# CC3200 register map
Vendor: Texas Instruments; Series: SimpleLink; File version: 1.0
Texas Instruments CC3200 SimpleLink Wi-Fi Cortex-M4 device generated from TI CCS target database CC_3200.xml
CPU: CM4 r0p1, little endian, MPU, no FPU, 3 interrupt priority bits
Registers are 32-bit, read-write, reset 0x0 unless marked. A register's access mark holds for its fields unless they carry their own. Offsets are from the block's base; lines under a group give offsets from that group; [hi:lo] are bit positions; {n}, {i} and the like mark numbered series; 'fields as' and 'values as' point back to an identical list; <NAME> marks a mode.

## Memory map
0x40000000 WDT size 0x1000
0x40004000 GPIO size 0x1000 — GPIOA0
0x40005000 GPIO size 0x1000 — GPIOA1
0x40006000 GPIO size 0x1000 — GPIOA2
0x40007000 GPIO size 0x1000 — GPIOA3
0x4000C000 UART size 0x1000 — UARTA0
0x4000D000 UART size 0x1000 — UARTA1
0x40020000 I2C size 0x1000 — I2CA0
0x40024000 GPIO size 0x1000 — GPIOA4
0x40030000 TIMER size 0x1000 — TIMERA0
0x40031000 TIMER size 0x1000 — TIMERA1
0x40032000 TIMER size 0x1000 — TIMERA2
0x40033000 TIMER size 0x1000 — TIMERA3
0x400F5000 STACK_DIE_CTRL size 0x1000
0x400F7000 COMMON_REG size 0x1000
0x400FD000 FLASH_CTRL size 0x1000 — FLASH_CONTROL
0x400FF000 UDMA size 0x1000
0x44010000 MMCHS size 0x1000 — SDHOST
0x44018000 CAMERA size 0x1000
0x4401C000 MCASP size 0x1000 — I2S
0x44020000 MCSPI size 0x1000 — SSPI
0x44021000 MCSPI size 0x1000 — GSPI
0x44022000 MCSPI size 0x1000 — LSPI
0x44025000 APPS_RCM size 0x1000 — ARCM
0x44026000 APPS_CONFIG size 0x1000
0x4402D000 GPRCM size 0x1000
0x4402E000 ADC size 0x1000
0x4402E000 OCP_SHARED size 0x1000
0x4402F000 HIB1P2 size 0x1000
0x4402F000 HIB3P3 size 0x1000
0x44030000 DTHE size 0x1000
0x44035000 SHAMD5 size 0x1000
0x44037000 AES size 0x1000
0x44039000 DES size 0x1000

## ADC
Base 0x4402E000
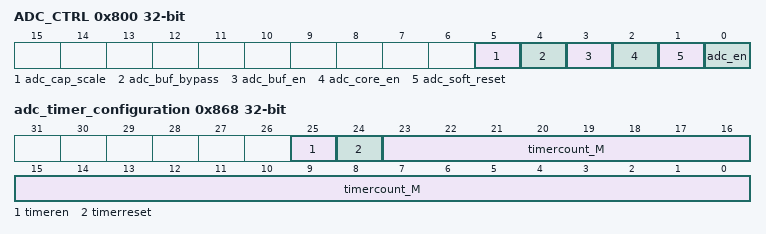
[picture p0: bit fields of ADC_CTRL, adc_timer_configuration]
0x800 ADC_CTRL — ADC_ADC_CTRL
  [5] adc_cap_scale — ADC_ADC_CTRL
  [4] adc_buf_bypass — ADC_ADC_CTRL
  [3] adc_buf_en — ADC_ADC_CTRL
  [2] adc_core_en — ADC_ADC_CTRL
  [1] adc_soft_reset — ADC_ADC_CTRL
  [0] adc_en — ADC_ADC_CTRL
{0x804+4i} adc_ch{i}_gain (i=0..7) — ADC_adc_ch{i}_gain
  [1:0] adc_channel{i}_gain_M
{0x824+4i} adc_ch{i}_irq_en (i=0..7) — ADC_adc_ch{i}_irq_en
  [3:0] adc_channel{i}_irq_en_M
{0x844+4i} adc_ch{i}_irq_status (i=0..7) — ADC_adc_ch{i}_irq_status
  [3:0] adc_channel{i}_irq_status_M
0x864 adc_dma_mode_en — ADC_adc_dma_mode_en
  [7:0] DMA_MODEenable_M
0x868 adc_timer_configuration — ADC_adc_timer_configuration
  [25] timeren — ADC_adc_timer_configuration
  [24] timerreset — ADC_adc_timer_configuration
  [23:0] timercount_M — ADC_adc_timer_configuration
0x870 adc_timer_current_count — ADC_adc_timer_current_count
  [16:0] timercurrentcount_M
{0x874+4i} channel{i}FIFODATA (i=0..7) — ADC_channel{i}FIFODATA
  [31:0] FIFO_RD_DATA_M
{0x894+4i} adc_ch{i}_fifo_lvl (i=0..7) — ADC_adc_ch{i}_fifo_lvl
  [2:0] adc_channel{i}_fifo_lvl_M
0x8B8 ADC_CH_ENABLE — ADC_ADC_CH_ENABLE

## AES
Base 0x44037000
0x00 KEY2_6 — AES_KEY2_6
  [31:0] KEY_M
0x04 KEY2_7 — AES_KEY2_7
  [31:0] KEY_M
0x08 KEY2_4 — AES_KEY2_4
  [31:0] KEY_M
0x0C KEY2_5 — AES_KEY2_5
  [31:0] KEY_M
0x10 KEY2_2 — AES_KEY2_2
  [31:0] KEY_M
0x14 KEY2_3 — AES_KEY2_3
  [31:0] KEY_M
0x18 KEY2_0 — AES_KEY2_0
  [31:0] KEY_M
0x1C KEY2_1 — AES_KEY2_1
  [31:0] KEY_M
0x20 KEY1_6 — AES_KEY1_6
  [31:0] KEY_M
0x24 KEY1_7 — AES_KEY1_7
  [31:0] KEY_M
0x28 KEY1_4 — AES_KEY1_4
  [31:0] KEY_M
0x2C KEY1_5 — AES_KEY1_5
  [31:0] KEY_M
0x30 KEY1_2 — AES_KEY1_2
  [31:0] KEY_M
0x34 KEY1_3 — AES_KEY1_3
  [31:0] KEY_M
0x38 KEY1_0 — AES_KEY1_0
  [31:0] KEY_M
0x3C KEY1_1 — AES_KEY1_1
  [31:0] KEY_M
{0x40+4i} IV_IN_{i} (i=0..3) — AES_IV_IN_{i}
  [31:0] DATA_M
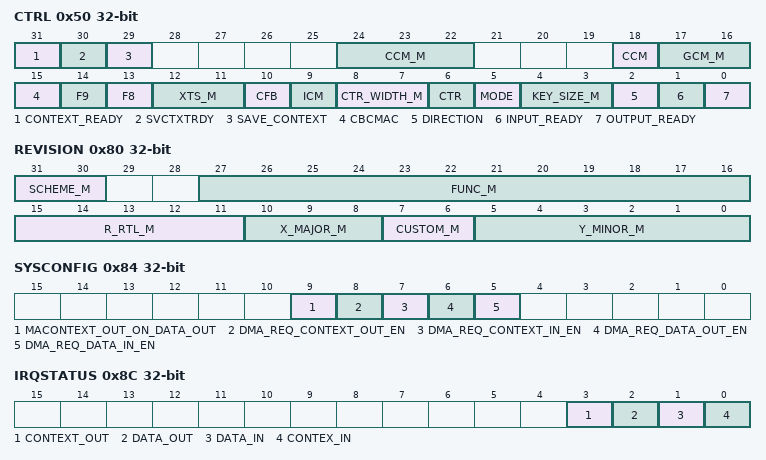
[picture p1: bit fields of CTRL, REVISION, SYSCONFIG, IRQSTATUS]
0x50 CTRL — AES_CTRL
  [31] CONTEXT_READY — AES_CTRL
  [30] SVCTXTRDY — AES_CTRL
  [29] SAVE_CONTEXT — AES_CTRL
  [24:22] CCM_M — AES_CTRL
  [18] CCM — AES_CTRL
  [17:16] GCM_M — AES_CTRL
  [15] CBCMAC — AES_CTRL
  [14] F9 — AES_CTRL
  [13] F8 — AES_CTRL
  [12:11] XTS_M — AES_CTRL
  [10] CFB — AES_CTRL
  [9] ICM — AES_CTRL
  [8:7] CTR_WIDTH_M — AES_CTRL
  [6] CTR — AES_CTRL
  [5] MODE — AES_CTRL
  [4:3] KEY_SIZE_M — AES_CTRL
  [2] DIRECTION — AES_CTRL
  [1] INPUT_READY — AES_CTRL
  [0] OUTPUT_READY — AES_CTRL
0x54 C_LENGTH_0 — AES_C_LENGTH_0
0x58 C_LENGTH_1 — AES_C_LENGTH_1
  [28:0] LENGTH_M
0x5C AUTH_LENGTH — AES_AUTH_LENGTH
  [31:0] AUTH_M
{0x60+4i} DATA_IN_{i} (i=0..3) — AES_DATA_IN_{i}
  [31:0] DATA_M
{0x70+4i} TAG_OUT_{i} (i=0..3) — AES_TAG_OUT_{i}
  [31:0] HASH_M
0x80 REVISION — AES_REVISION
  [31:30] SCHEME_M — AES_REVISION
  [27:16] FUNC_M — AES_REVISION
  [15:11] R_RTL_M — AES_REVISION
  [10:8] X_MAJOR_M — AES_REVISION
  [7:6] CUSTOM_M — AES_REVISION
  [5:0] Y_MINOR_M — AES_REVISION
0x84 SYSCONFIG — AES_SYSCONFIG
  [9] MACONTEXT_OUT_ON_DATA_OUT — AES_SYSCONFIG
  [8] DMA_REQ_CONTEXT_OUT_EN — AES_SYSCONFIG
  [7] DMA_REQ_CONTEXT_IN_EN — AES_SYSCONFIG
  [6] DMA_REQ_DATA_OUT_EN — AES_SYSCONFIG
  [5] DMA_REQ_DATA_IN_EN — AES_SYSCONFIG
0x88 SYSSTATUS — AES_SYSSTATUS
  [0] RESETDONE
0x8C IRQSTATUS — AES_IRQSTATUS
  [3] CONTEXT_OUT — AES_IRQSTATUS
  [2] DATA_OUT — AES_IRQSTATUS
  [1] DATA_IN — AES_IRQSTATUS
  [0] CONTEX_IN — AES_IRQSTATUS
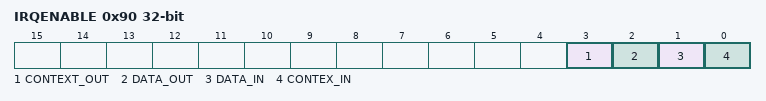
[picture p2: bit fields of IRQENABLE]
0x90 IRQENABLE — AES_IRQENABLE
  [3] CONTEXT_OUT — AES_IRQENABLE
  [2] DATA_OUT — AES_IRQENABLE
  [1] DATA_IN — AES_IRQENABLE
  [0] CONTEX_IN — AES_IRQENABLE
